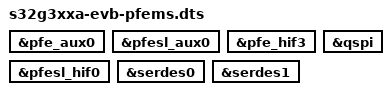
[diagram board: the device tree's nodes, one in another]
// SPDX-License-Identifier: GPL-2.0-or-later
/*
 * Device Tree file for S32G-PROCEVB with S32G3 + S32GRV-VNP-PLAT boards
 * PFE Master/Slave mode supported
 *
 * Copyright 2022-2024 NXP
 */

#include "s32g3xxa-evb.dtsi"
#include "s32g-pfe-slave.dtsi"

&pfe_aux0 {
	status = "okay";
};

&pfesl_aux0 {
	status = "okay";
};

&pfe_hif3 {
	status = "okay";
};

&pfesl_hif0 {
	status = "okay";
};

&qspi {
	status = "okay";
};

&serdes0 {
	status = "okay";
};

&serdes1 {
	status = "okay";
};
